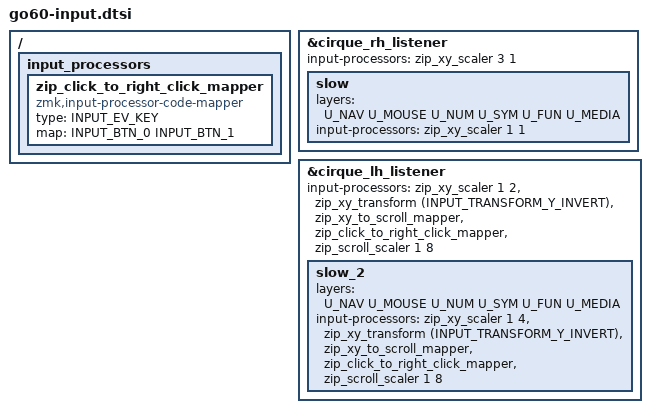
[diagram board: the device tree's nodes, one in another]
#include <input/processors.dtsi>
#include <dt-bindings/zmk/input_transform.h>

/ {
    input_processors {
        zip_click_to_right_click_mapper: zip_click_to_right_click_mapper {
            compatible = "zmk,input-processor-code-mapper";
            #input-processor-cells = <0>;
            type = <INPUT_EV_KEY>;
            map = <INPUT_BTN_0 INPUT_BTN_1>;
        };
    };
};

/* Custom Device-tree */


/* Input Listeners */
&cirque_rh_listener {
    input-processors = <&zip_xy_scaler 3 1>;
    slow {
        layers = <U_NAV U_MOUSE U_NUM U_SYM U_FUN U_MEDIA>;
        input-processors = <&zip_xy_scaler 1 1>;
    };
};

&cirque_lh_listener {
    input-processors = <&zip_xy_scaler 1 2>, <&zip_xy_transform (INPUT_TRANSFORM_Y_INVERT)>, <&zip_xy_to_scroll_mapper>, <&zip_click_to_right_click_mapper>, <&zip_scroll_scaler 1 8>;
    slow_2 {
        layers = <U_NAV U_MOUSE U_NUM U_SYM U_FUN U_MEDIA>;
        input-processors = <&zip_xy_scaler 1 4>, <&zip_xy_transform (INPUT_TRANSFORM_Y_INVERT)>, <&zip_xy_to_scroll_mapper>, <&zip_click_to_right_click_mapper>, <&zip_scroll_scaler 1 8>;
    };
};


